# ESP32-C3 register map
Vendor: ESPRESSIF SYSTEMS (SHANGHAI) CO., LTD.; Series: ESP32 C-Series; File version: 19
CPU: RV32IMC r0p0, little endian, no MPU, no FPU, 0 interrupt priority bits
Address unit: 32 bits
Registers are 32-bit, read-write, reset 0x0 unless marked. A register's access mark holds for its fields unless they carry their own. Offsets are from the block's base; [hi:lo] are bit positions; lines under a group give offsets from that group; {n}, {i} and the like mark numbered series.

## IO_MUX — Input/Output Multiplexer
Base 0x60009000
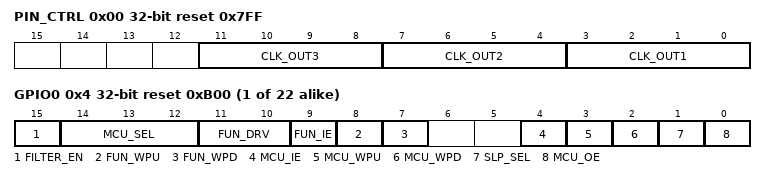
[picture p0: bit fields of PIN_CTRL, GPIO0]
0x00 PIN_CTRL reset 0x7FF — Clock Output Configuration Register
  [11:8] CLK_OUT3 — If you want to output clock for I2S to CLK_OUT_out3, set this register to 0x0. CLK_OUT_out3 can be found in peripheral output signals.
  [7:4] CLK_OUT2 — If you want to output clock for I2S to CLK_OUT_out2, set this register to 0x0. CLK_OUT_out2 can be found in peripheral output signals.
  [3:0] CLK_OUT1 — If you want to output clock for I2S to CLK_OUT_out1, set this register to 0x0. CLK_OUT_out1 can be found in peripheral output signals.
{0x4+4i} GPIO{i} (i=0..21) reset 0xB00 — IO MUX Configure Register for pad XTAL_32K_P
  [15] FILTER_EN — Enable filter for pin input signals. 1: Filter enabled; 2: Filter disabled.
  [14:12] MCU_SEL — Select IO MUX function for this signal. 0: Select Function 1; 1: Select Function 2; etc.
  [11:10] FUN_DRV — Select the drive strength of the pad. 0: ~5 mA; 1: ~10mA; 2: ~20mA; 3: ~40mA.
  [9] FUN_IE — Input enable of the pad. 1: input enabled; 0: input disabled.
  [8] FUN_WPU — Pull-up enable of the pad. 1: internal pull-up enabled; 0: internal pull-up disabled.
  [7] FUN_WPD — Pull-down enable of the pad. 1: internal pull-down enabled; 0: internal pull-down disabled.
  [4] MCU_IE — Input enable of the pad during sleep mode. 1: input enabled; 0: input disabled.
  [3] MCU_WPU — Pull-up enable of the pad during sleep mode. 1: internal pull-up enabled; 0: internal pull-up disabled.
  [2] MCU_WPD — Pull-down enable of the pad in sleep mode. 1: internal pull-down enabled; 0: internal pull-down disabled.
  [1] SLP_SEL — Sleep mode selection of this pad. Set to 1 to put the pad in pad mode.
  [0] MCU_OE — Output enable of the pad in sleep mode. 1: output enabled; 0: output disabled.
0xFC DATE — IO MUX Version Control Register

## I2C_ANA_MST — I2C_MST_ANA Peripheral
Base 0x6000E040
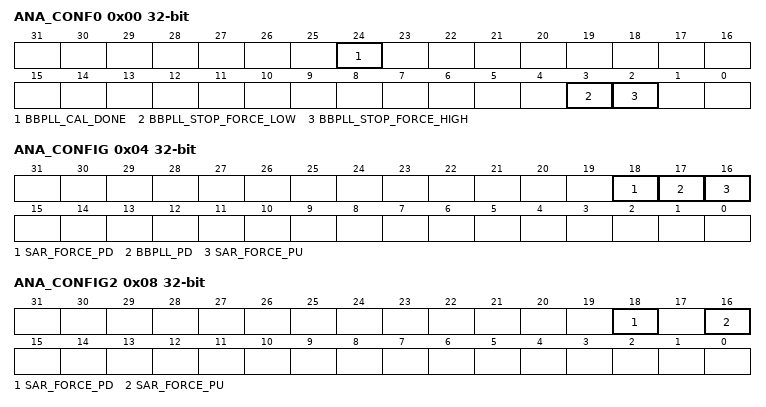
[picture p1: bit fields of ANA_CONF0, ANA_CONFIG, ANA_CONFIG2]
0x00 ANA_CONF0
  [24] BBPLL_CAL_DONE — ?
  [3] BBPLL_STOP_FORCE_LOW — ?
  [2] BBPLL_STOP_FORCE_HIGH — ?
0x04 ANA_CONFIG
  [18] SAR_FORCE_PD — ?
  [17] BBPLL_PD — Clear to enable BBPLL
  [16] SAR_FORCE_PU — ?
0x08 ANA_CONFIG2
  [18] SAR_FORCE_PD — ?
  [16] SAR_FORCE_PU — ?

## LEDC — LED Control PWM (Pulse Width Modulation)
Base 0x60019000
{0x0+0x14*i} CH{i} (i=0..5) group — Cluster CH{i}, containing CH?_CONF0, CH?_HPOINT, CH?_DUTY, CH?_CONF1, CH?_DUTY_R
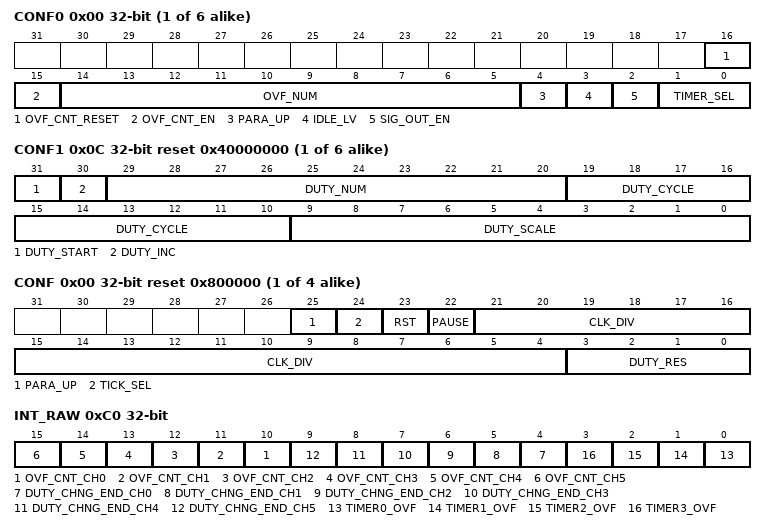
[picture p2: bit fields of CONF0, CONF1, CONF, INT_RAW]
  0x00 CONF0 access per field — LEDC_LSCH0_CONF0.
    [16] OVF_CNT_RESET wo — reg_ovf_cnt_reset_lsch0.
    [15] OVF_CNT_EN rw — reg_ovf_cnt_en_lsch0.
    [14:5] OVF_NUM rw — reg_ovf_num_lsch0.
    [4] PARA_UP wo — reg_para_up_lsch0.
    [3] IDLE_LV rw — reg_idle_lv_lsch0.
    [2] SIG_OUT_EN rw — reg_sig_out_en_lsch0.
    [1:0] TIMER_SEL rw — reg_timer_sel_lsch0.
  0x04 HPOINT — LEDC_LSCH0_HPOINT.
    [13:0] HPOINT — reg_hpoint_lsch0.
  0x08 DUTY — LEDC_LSCH0_DUTY.
    [18:0] DUTY — reg_duty_lsch0.
  0x0C CONF1 reset 0x40000000 — LEDC_LSCH0_CONF1.
    [31] DUTY_START — reg_duty_start_lsch0.
    [30] DUTY_INC — reg_duty_inc_lsch0.
    [29:20] DUTY_NUM — reg_duty_num_lsch0.
    [19:10] DUTY_CYCLE — reg_duty_cycle_lsch0.
    [9:0] DUTY_SCALE — reg_duty_scale_lsch0.
  0x10 DUTY_R ro — LEDC_LSCH0_DUTY_R.
    [18:0] DUTY_R — reg_duty_lsch0_r.
{0xA0+8i} TIMER{i} (i=0..3) group — Cluster TIMER{i}, containing TIMER?_CONF, TIMER?_VALUE
  0x00 CONF access per field reset 0x800000 — LEDC_LSTIMER0_CONF.
    [25] PARA_UP wo — reg_lstimer0_para_up.
    [24] TICK_SEL rw — reg_tick_sel_lstimer0.
    [23] RST rw — reg_lstimer0_rst.
    [22] PAUSE rw — reg_lstimer0_pause.
    [21:4] CLK_DIV rw — reg_clk_div_lstimer0.
    [3:0] DUTY_RES rw — reg_lstimer0_duty_res.
  0x04 VALUE ro — LEDC_LSTIMER0_VALUE.
    [13:0] CNT — reg_lstimer0_cnt.
0xC0 INT_RAW — LEDC_INT_RAW.
  [n+10] OVF_CNT_CH{n} (n=0..5) — Interrupt raw bit for channel {n}. Triggered when the OVF_CNT has reached the value specified by LEDC.CHx.CONF0.OVF_NUM.
  [n+4] DUTY_CHNG_END_CH{n} (n=0..5) — Interrupt raw bit for channel {n}. Triggered when the gradual change of duty has finished.
  [n] TIMER{n}_OVF (n=0..3) — reg_lstimer{n}_ovf_int_raw.
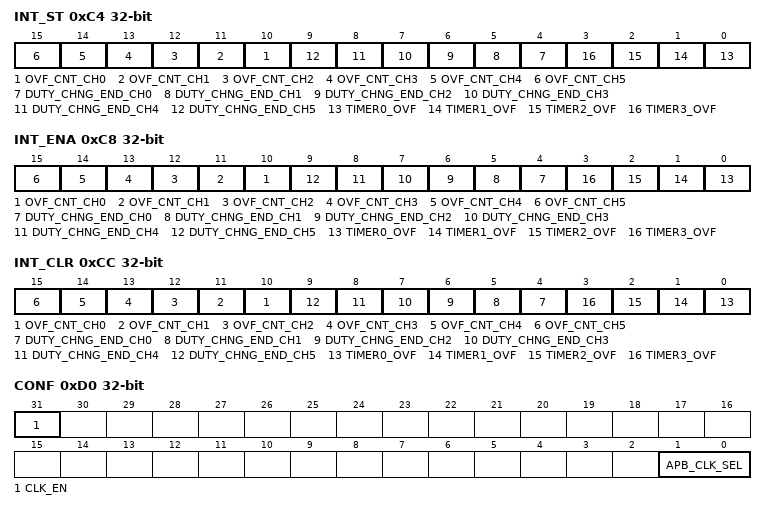
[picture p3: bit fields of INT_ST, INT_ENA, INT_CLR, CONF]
0xC4 INT_ST ro — LEDC_INT_ST.
  [n+10] OVF_CNT_CH{n} (n=0..5) — This is the masked interrupt status bit for the LEDC.INT_RAW.OVF_CNT_CH{n} interrupt when LEDC.INT_ENA.OVF_CNT_CHx is set to 1.
  [n+4] DUTY_CHNG_END_CH{n} (n=0..5) — This is the masked interrupt status bit for the DUTY_CHNG_END_CH{n} interrupt when LEDC.INT_ENA.DUTY_CHNG_END_CHx is set to 1.
  [n] TIMER{n}_OVF (n=0..3) — This is the masked interrupt status bit for the TIMER{n}_OVF interrupt when LEDC.INT_ENA.TIMERx_OVF is set to 1.
0xC8 INT_ENA — LEDC_INT_ENA.
  [n+10] OVF_CNT_CH{n} (n=0..5) — The interrupt enable bit for the OVF_CNT_CH{n} interrupt.
  [n+4] DUTY_CHNG_END_CH{n} (n=0..5) — The interrupt enable bit for the DUTY_CHNG_END_CH{n} interrupt.
  [n] TIMER{n}_OVF (n=0..3) — The interrupt enable bit for the TIMER{n}_OVF interrupt.
0xCC INT_CLR wo — LEDC_INT_CLR.
  [n+10] OVF_CNT_CH{n} (n=0..5) write-1-clears — Set this bit to clear the OVF_CNT_CH{n} interrupt.
  [n+4] DUTY_CHNG_END_CH{n} (n=0..5) write-1-clears — Set this bit to clear the DUTY_CHNG_END_CH{n} interrupt.
  [n] TIMER{n}_OVF (n=0..3) write-1-clears — Set this bit to clear the TIMER{n}_OVF interrupt.
0xD0 CONF — LEDC_CONF.
  [31] CLK_EN — reg_clk_en.
  [1:0] APB_CLK_SEL — reg_apb_clk_sel.
0xFC DATE — LEDC_DATE.
